AUTOSAR XML (schema 4-2-2)
package /ComponentTypes
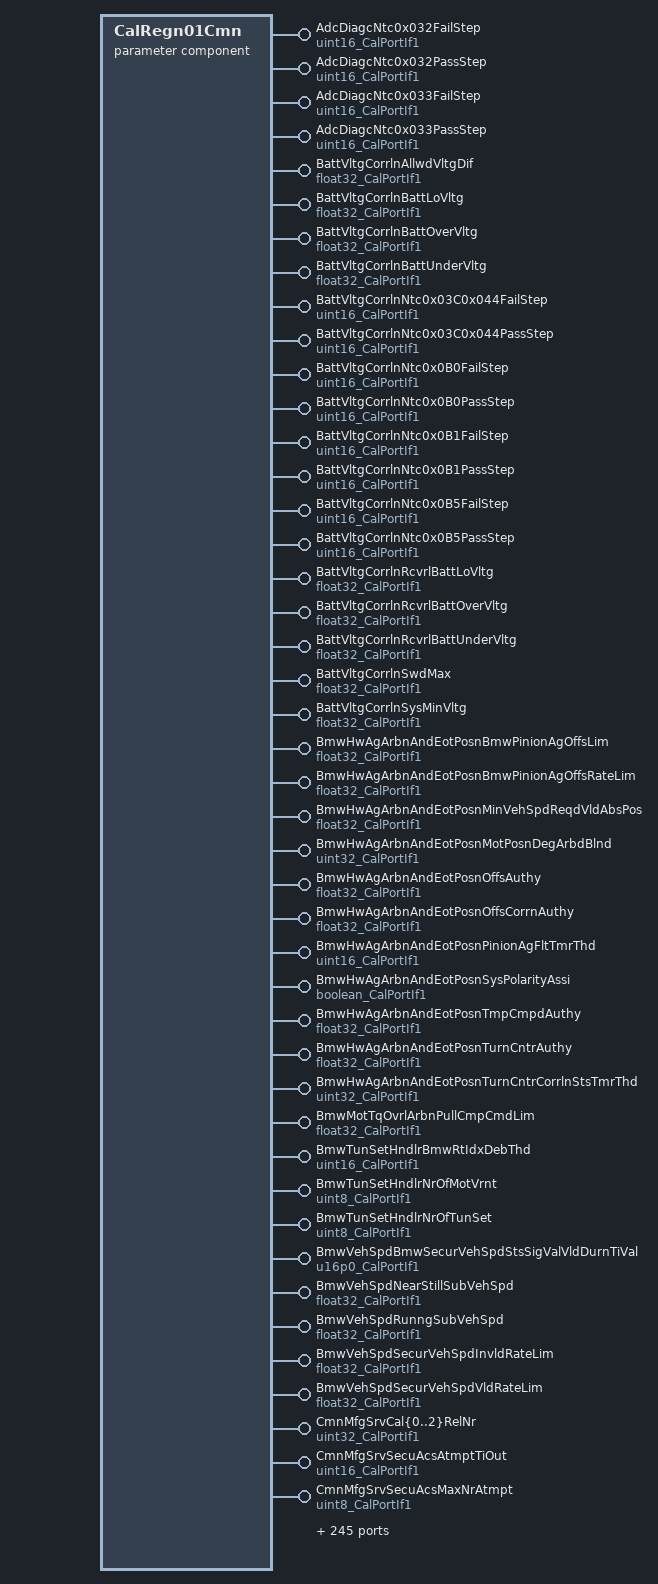
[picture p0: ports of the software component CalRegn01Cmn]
  parameter sw component type CalRegn01Cmn
    293 x provide port:
      AdcDiagcNtc0x032FailStep: parameter-provide-com-spec{init-value=6554, parameter=Val}, provided-interface=uint16_CalPortIf1
      AdcDiagcNtc0x032PassStep: parameter-provide-com-spec{init-value=65, parameter=Val}, provided-interface=uint16_CalPortIf1
      AdcDiagcNtc0x033FailStep: parameter-provide-com-spec{init-value=6554, parameter=Val}, provided-interface=uint16_CalPortIf1
      AdcDiagcNtc0x033PassStep: parameter-provide-com-spec{init-value=65, parameter=Val}, provided-interface=uint16_CalPortIf1
      BattVltgCorrlnAllwdVltgDif: parameter-provide-com-spec{init-value=0.73, parameter=Val}, provided-interface=float32_CalPortIf1
      BattVltgCorrlnBattLoVltg: parameter-provide-com-spec{init-value=10, parameter=Val}, provided-interface=float32_CalPortIf1
      BattVltgCorrlnBattOverVltg: parameter-provide-com-spec{init-value=16, parameter=Val}, provided-interface=float32_CalPortIf1
      BattVltgCorrlnBattUnderVltg: parameter-provide-com-spec{init-value=9, parameter=Val}, provided-interface=float32_CalPortIf1
      BattVltgCorrlnNtc0x03C0x044FailStep: parameter-provide-com-spec{init-value=410, parameter=Val}, provided-interface=uint16_CalPortIf1
      BattVltgCorrlnNtc0x03C0x044PassStep: parameter-provide-com-spec{init-value=272, parameter=Val}, provided-interface=uint16_CalPortIf1
      BattVltgCorrlnNtc0x0B0FailStep: parameter-provide-com-spec{init-value=327, parameter=Val}, provided-interface=uint16_CalPortIf1
      BattVltgCorrlnNtc0x0B0PassStep: parameter-provide-com-spec{init-value=327, parameter=Val}, provided-interface=uint16_CalPortIf1
      BattVltgCorrlnNtc0x0B1FailStep: parameter-provide-com-spec{init-value=327, parameter=Val}, provided-interface=uint16_CalPortIf1
      BattVltgCorrlnNtc0x0B1PassStep: parameter-provide-com-spec{init-value=327, parameter=Val}, provided-interface=uint16_CalPortIf1
      BattVltgCorrlnNtc0x0B5FailStep: parameter-provide-com-spec{init-value=327, parameter=Val}, provided-interface=uint16_CalPortIf1
      BattVltgCorrlnNtc0x0B5PassStep: parameter-provide-com-spec{init-value=327, parameter=Val}, provided-interface=uint16_CalPortIf1
      BattVltgCorrlnRcvrlBattLoVltg: parameter-provide-com-spec{init-value=10.5, parameter=Val}, provided-interface=float32_CalPortIf1
      BattVltgCorrlnRcvrlBattOverVltg: parameter-provide-com-spec{init-value=15.5, parameter=Val}, provided-interface=float32_CalPortIf1
      BattVltgCorrlnRcvrlBattUnderVltg: parameter-provide-com-spec{init-value=9.5, parameter=Val}, provided-interface=float32_CalPortIf1
      BattVltgCorrlnSwdMax: parameter-provide-com-spec{init-value=16, parameter=Val}, provided-interface=float32_CalPortIf1
      BattVltgCorrlnSysMinVltg: parameter-provide-com-spec{init-value=6, parameter=Val}, provided-interface=float32_CalPortIf1
      BmwHwAgArbnAndEotPosnBmwPinionAgOffsLim: parameter-provide-com-spec{init-value=0, parameter=Val}, provided-interface=float32_CalPortIf1
      BmwHwAgArbnAndEotPosnBmwPinionAgOffsRateLim: parameter-provide-com-spec{init-value=50, parameter=Val}, provided-interface=float32_CalPortIf1
      BmwHwAgArbnAndEotPosnMinVehSpdReqdVldAbsPos: parameter-provide-com-spec{init-value=18, parameter=Val}, provided-interface=float32_CalPortIf1
      BmwHwAgArbnAndEotPosnMotPosnDegArbdBlnd: parameter-provide-com-spec{init-value=200, parameter=Val}, provided-interface=uint32_CalPortIf1
      BmwHwAgArbnAndEotPosnOffsAuthy: parameter-provide-com-spec{init-value=1, parameter=Val}, provided-interface=float32_CalPortIf1
      BmwHwAgArbnAndEotPosnOffsCorrnAuthy: parameter-provide-com-spec{init-value=0.8, parameter=Val}, provided-interface=float32_CalPortIf1
      BmwHwAgArbnAndEotPosnPinionAgFltTmrThd: parameter-provide-com-spec{init-value=20, parameter=Val}, provided-interface=uint16_CalPortIf1
      BmwHwAgArbnAndEotPosnSysPolarityAssi: parameter-provide-com-spec{init-value=1, parameter=Logl}, provided-interface=boolean_CalPortIf1
      BmwHwAgArbnAndEotPosnTmpCmpdAuthy: parameter-provide-com-spec{init-value=0.6, parameter=Val}, provided-interface=float32_CalPortIf1
      BmwHwAgArbnAndEotPosnTurnCntrAuthy: parameter-provide-com-spec{init-value=1, parameter=Val}, provided-interface=float32_CalPortIf1
      BmwHwAgArbnAndEotPosnTurnCntrCorrlnStsTmrThd: parameter-provide-com-spec{init-value=50, parameter=Val}, provided-interface=uint32_CalPortIf1
      BmwMotTqOvrlArbnPullCmpCmdLim: parameter-provide-com-spec{init-value=8.8, parameter=Val}, provided-interface=float32_CalPortIf1
      BmwTunSetHndlrBmwRtIdxDebThd: parameter-provide-com-spec{init-value=120, parameter=Val}, provided-interface=uint16_CalPortIf1
      BmwTunSetHndlrNrOfMotVrnt: parameter-provide-com-spec{init-value=4, parameter=Val}, provided-interface=uint8_CalPortIf1
      BmwTunSetHndlrNrOfTunSet: parameter-provide-com-spec{init-value=7, parameter=Val}, provided-interface=uint8_CalPortIf1
      BmwVehSpdBmwSecurVehSpdStsSigValVldDurnTiVal: parameter-provide-com-spec{init-value=300, parameter=Val}, provided-interface=u16p0_CalPortIf1
      BmwVehSpdNearStillSubVehSpd: parameter-provide-com-spec{init-value=9, parameter=Val}, provided-interface=float32_CalPortIf1
      BmwVehSpdRunngSubVehSpd: parameter-provide-com-spec{init-value=130, parameter=Val}, provided-interface=float32_CalPortIf1
      BmwVehSpdSecurVehSpdInvldRateLim: parameter-provide-com-spec{init-value=50, parameter=Val}, provided-interface=float32_CalPortIf1
      BmwVehSpdSecurVehSpdVldRateLim: parameter-provide-com-spec{init-value=50, parameter=Val}, provided-interface=float32_CalPortIf1
      CmnMfgSrvCal{0..2}RelNr: parameter-provide-com-spec{init-value=0, parameter=Val}, provided-interface=uint32_CalPortIf1
      CmnMfgSrvSecuAcsAtmptTiOut: parameter-provide-com-spec{init-value=0, parameter=Val}, provided-interface=uint16_CalPortIf1
      CmnMfgSrvSecuAcsMaxNrAtmpt: parameter-provide-com-spec{init-value=0, parameter=Val}, provided-interface=uint8_CalPortIf1
      CmplncErrHwAgNonLinCmplncDepTblY: parameter-provide-com-spec{init-value=6 x 0, parameter=Ary1D}, provided-interface=Ary1D_u1p15_6_CalPortIf1
      CmplncErrHwAgNonLinCmplncIndTblX: parameter-provide-com-spec{init-value=[0, 1024, 3072, 6144, 10240, 16384], parameter=Ary1D}, provided-interface=Ary1D_u5p11_6_CalPortIf1
      CmplncErrMotAgNonLinCmplncDepTblY: parameter-provide-com-spec{init-value=6 x 0, parameter=Ary1D}, provided-interface=Ary1D_u8p8_6_CalPortIf1
      CmplncErrMotAgNonLinCmplncIndTblX: parameter-provide-com-spec{init-value=[0, 1024, 3072, 6144, 10240, 16384], parameter=Ary1D}, provided-interface=Ary1D_u5p11_6_CalPortIf1
      CurrMeasArbnMaxStallCntr: parameter-provide-com-spec{init-value=20, parameter=Val}, provided-interface=uint8_CalPortIf1
      CurrMeasCorrlnMaxErrCurr: parameter-provide-com-spec{init-value=12, parameter=Val}, provided-interface=float32_CalPortIf1
      CurrMeasCorrlnMaxStallCntr: parameter-provide-com-spec{init-value=200, parameter=Val}, provided-interface=uint8_CalPortIf1
      CurrMeasCorrlnNtc0x04DFailStep: parameter-provide-com-spec{init-value=512, parameter=Val}, provided-interface=uint16_CalPortIf1
      CurrMeasCorrlnNtc0x04DPassStep: parameter-provide-com-spec{init-value=512, parameter=Val}, provided-interface=uint16_CalPortIf1
      CurrMeasEolFixdPwmPerd: parameter-provide-com-spec{init-value=62500, parameter=Val}, provided-interface=uint32_CalPortIf1
      CurrMeasEolGainMax: parameter-provide-com-spec{init-value=76, parameter=Val}, provided-interface=float32_CalPortIf1
      CurrMeasEolGainMin: parameter-provide-com-spec{init-value=56, parameter=Val}, provided-interface=float32_CalPortIf1
      CurrMeasEolGainNom: parameter-provide-com-spec{init-value=66.66, parameter=Val}, provided-interface=float32_CalPortIf1
      CurrMeasEolGainNrOfSample: parameter-provide-com-spec{init-value=5, parameter=Val}, provided-interface=uint16_CalPortIf1
      CurrMeasEolGainNumer: parameter-provide-com-spec{init-value=45, parameter=Val}, provided-interface=float32_CalPortIf1
      CurrMeasEolMaxMotVel: parameter-provide-com-spec{init-value=16, parameter=Val}, provided-interface=float32_CalPortIf1
      CurrMeasEolOffsHiBrdgVltgMin: parameter-provide-com-spec{init-value=262500, parameter=Val}, provided-interface=float32_CalPortIf1
      CurrMeasEolOffsHiCmuOffs: parameter-provide-com-spec{init-value=50000, parameter=Val}, provided-interface=uint32_CalPortIf1
      CurrMeasEolOffsLoCmuOffs: parameter-provide-com-spec{init-value=6250, parameter=Val}, provided-interface=uint32_CalPortIf1
      CurrMeasEolOffsMax: parameter-provide-com-spec{init-value=2.8, parameter=Val}, provided-interface=float32_CalPortIf1
      CurrMeasEolOffsMin: parameter-provide-com-spec{init-value=2.3, parameter=Val}, provided-interface=float32_CalPortIf1
      CurrMeasEolOffsNom: parameter-provide-com-spec{init-value=2.5, parameter=Val}, provided-interface=float32_CalPortIf1
      CurrMeasEolOffsNrOfSample: parameter-provide-com-spec{init-value=20, parameter=Val}, provided-interface=uint16_CalPortIf1
      CurrMeasEolTranCntrThd: parameter-provide-com-spec{init-value=5, parameter=Val}, provided-interface=uint8_CalPortIf1
      CurrMeasMinRqrdPhaOnTi: parameter-provide-com-spec{init-value=11000, parameter=Val}, provided-interface=uint32_CalPortIf1
      CurrMeasMotAgCompuDly: parameter-provide-com-spec{init-value=30000, parameter=Val}, provided-interface=uint32_CalPortIf1
      CurrMeasMotCurrAdcVlyWrmIninMax: parameter-provide-com-spec{init-value=3, parameter=Val}, provided-interface=float32_CalPortIf1
      CurrMeasMotCurrAdcVlyWrmIninMin: parameter-provide-com-spec{init-value=2, parameter=Val}, provided-interface=float32_CalPortIf1
      CurrMeasNtc0x05DFailStep: parameter-provide-com-spec{init-value=16384, parameter=Val}, provided-interface=uint16_CalPortIf1
      CurrMeasNtc0x05DPassStep: parameter-provide-com-spec{init-value=16384, parameter=Val}, provided-interface=uint16_CalPortIf1
      DiagcMgrFltResp: parameter-provide-com-spec{init-value=[0, 34560, 34560, 34560, 34560, 34560, 34560, 34560, 34560, 34560, 34560, 34560, 34560, 34560, 34560, 34560, 34560, 34560, 34560, 34560, 34560, 34560, 34560, 34560, 34560, 34560, 34560, 34560, 34560, 34560, 34560, 34560, 34560, 34560, 34560, 34560, 34560, 34560, 34560, 34560, 34560, 34560, 34560, 34560, 34560, 34560, 34560, 34560, 34560, 34560, 34560, 34560, 34560, 34560, 34560, 34560, 34560, 34560, 34560, 34560, 34560, 34560, 34560, 34560, 34560, 34560, 34560, 34560, 34560, 34560, 34560, 34560, 34560, 34560, 34560, 34560, 34560, 34560, 34560, 34560, 34560, 34560, 34560, 34560, 34560, 34560, 34560, 34560, 34560, 34560, 34560, 34560, 34560, 34560, 34560, 34560, 34560, 34560, 34560, 34560, 34560, 34560, 34560, 34560, 34560, 34560, 34560, 34560, 34560, 34560, 34560, 34560, 34560, 34560, 34560, 34560, 34560, 34560, 34560, 34560, 34560, 34560, 34560, 34560, 34560, 34560, 34560, 34560, 34560, 34560, 34560, 34560, 34560, 34560, 34560, 34560, 34560, 34560, 34560, 34560, 34560, 34560, 34560, 34560, 34560, 34560, 34560, 34560, 34560, 34560, 34560, 34560, 34560, 34560, 34560, 34560, 34560, 34560, 34560, 34560, 34560, 34560, 34560, 34560, 34560, 34560, 34560, 34560, 34560, 34560, 34560, 34560, 34560, 34560, 34560, 34560, 34560, 34560, 34560, 34560, 34560, 34560, 34560, 34560, 34560, 34560, 34560, 34560, 34560, 34560, 34560, 34560, 34560, 34560, 34560, 34560, 34560, 34560, 34560, 34560, 34560, 34560, 34560, 34560, 34560, 34560, 34560, 34560, 34560, 34560, 34560, 34560, 34560, 34560, 34560, 34560, 34560, 34560, 34560, 34560, 34560, 34560, 34560, 34560, 34560, 34560, 34560, 34560, 34560, 34560, 34560, 34560, 34560, 34560, 34560, 34560, 34560, 34560, 34560, 34560, 34560, 34560, 34560, 34560, 34560, 34560, 34560, 34560, 34560, 34560, 34560, 34560, 34560, 34560, 34560, 34560, 34560, 34560, 34560, 34560, 34560, 34560, 34560, 34560, 34560, 34560, 34560, 34560, 34560, 34560, 34560, 34560, 34560, 34560, 34560, 34560, 34560, 34560, 34560, 34560, 34560, 34560, 34560, 34560, 34560, 34560, 34560, 34560, 34560, 34560, 34560, 34560, 34560, 34560, 34560, 34560, 34560, 34560, 34560, 34560, 34560, 34560, 34560, 34560, 34560, 34560, 34560, 34560, 34560, 34560, 34560, 34560, 34560, 34560, 34560, 34560, 34560, 34560, 34560, 34560, 34560, 34560, 34560, 34560, 34560, 34560, 34560, 34560, 34560, 34560, 34560, 34560, 34560, 34560, 34560, 34560, 34560, 34560, 34560, 34560, 34560, 34560, 34560, 34560, 34560, 34560, 34560, 34560, 34560, 34560, 34560, 34560, 34560, 34560, 34560, 34560, 34560, 34560, 34560, 34560, 34560, 34560, 34560, 34560, 34560, 34560, 34560, 34560, 34560, 34560, 34560, 34560, 34560, 34560, 34560, 34560, 34560, 34560, 34560, 34560, 34560, 34560, 34560, 34560, 34560, 34560, 34560, 34560, 34560, 34560, 34560, 34560, 34560, 34560, 34560, 34560, 34560, 34560, 34560, 34560, 34560, 34560, 34560, 34560, 34560, 34560, 34560, 34560, 34560, 34560, 34560, 34560, 34560, 34560, 34560, 34560, 34560, 34560, 34560, 34560, 34560, 34560, 34560, 34560, 34560, 34560, 34560, 34560, 34560, 34560, 34560, 34560, 34560, 34560, 34560, 34560, 34560, 34560, 34560, 34560, 34560, 34560, 34560, 34560, 34560, 34560, 34560, 34560, 34560, 34560, 34560, 34560, 34560, 34560, 34560, 34560, 34560, 34560, 34560, 34560, 34560, 34560, 34560, 34560, 34560, 34560, 34560, 34560, 34560, 34560, 34560, 34560, 34560, 34560, 34560, 34560, 34560, 34560, 34560, 34560, 34560, 34560, 34560, 34560, 34560, 34560, 34560, 34560, 34560, 34560, 34560, 34560, 34560, 34560, 34560, 34560, 34560, 34560, 34560, 34560, 34560, 34560, 34560, 34560, 34560, 34560, 34560, 34560, 34560, 34560, 34560, 34560], parameter=Ary1D}, provided-interface=Ary1D_u16_512_CalPortIf1
      ElecPwrCnsCtrlrInpR: parameter-provide-com-spec{init-value=0.0005, parameter=Val}, provided-interface=float32_CalPortIf1
      GateDrv0CtrlErrFilFrq: parameter-provide-com-spec{init-value=1.8, parameter=Val}, provided-interface=float32_CalPortIf1
      GateDrv0CtrlErrOffs: parameter-provide-com-spec{init-value=0, parameter=Val}, provided-interface=uint32_CalPortIf1
      GateDrv0CtrlErrThd: parameter-provide-com-spec{init-value=180000, parameter=Val}, provided-interface=uint32_CalPortIf1
      GateDrv0CtrlNtcNr0x050FailStep: parameter-provide-com-spec{init-value=4096, parameter=Val}, provided-interface=uint16_CalPortIf1
      GateDrv0CtrlNtcNr0x050PassStep: parameter-provide-com-spec{init-value=2048, parameter=Val}, provided-interface=uint16_CalPortIf1
      GateDrv0CtrlNtcNr0x051FailStep: parameter-provide-com-spec{init-value=4096, parameter=Val}, provided-interface=uint16_CalPortIf1
      GateDrv0CtrlNtcNr0x051PassStep: parameter-provide-com-spec{init-value=2048, parameter=Val}, provided-interface=uint16_CalPortIf1
      GateDrv0CtrlNtcNr0x055FailStep: parameter-provide-com-spec{init-value=4096, parameter=Val}, provided-interface=uint16_CalPortIf1
      GateDrv0CtrlNtcNr0x055PassStep: parameter-provide-com-spec{init-value=2048, parameter=Val}, provided-interface=uint16_CalPortIf1
      GateDrv0CtrlUnit0Cfg2WrVal: parameter-provide-com-spec{init-value=2832, parameter=Val}, provided-interface=uint16_CalPortIf1
      GateDrv0CtrlUnit0Cfg3WrVal: parameter-provide-com-spec{init-value=3598, parameter=Val}, provided-interface=uint16_CalPortIf1
      GateDrv0CtrlUnit0Cfg4WrVal: parameter-provide-com-spec{init-value=4622, parameter=Val}, provided-interface=uint16_CalPortIf1
      GateDrv0CtrlUnit0Cfg7WrVal: parameter-provide-com-spec{init-value=7924, parameter=Val}, provided-interface=uint16_CalPortIf1
      HiLoadStallLimrMotTqCmdFetMtgtnEnaFilFrq: parameter-provide-com-spec{init-value=2, parameter=Val}, provided-interface=float32_CalPortIf1
      HiLoadStallLimrMotTqCmdFilFrq: parameter-provide-com-spec{init-value=2, parameter=Val}, provided-interface=float32_CalPortIf1
      HwTq4MeasHwTq4PrtclFltFailStep: parameter-provide-com-spec{init-value=2521, parameter=Val}, provided-interface=uint16_CalPortIf1
      HwTq4MeasHwTq4PrtclFltPassStep: parameter-provide-com-spec{init-value=1000, parameter=Val}, provided-interface=uint16_CalPortIf1
      HwTq4MeasHwTqRngHiLim: parameter-provide-com-spec{init-value=4.75, parameter=Val}, provided-interface=float32_CalPortIf1
      HwTq4MeasHwTqRngLoLim: parameter-provide-com-spec{init-value=0.25, parameter=Val}, provided-interface=float32_CalPortIf1
      HwTq4MeasMovgAvrgFilEna: parameter-provide-com-spec{init-value=0, parameter=Logl}, provided-interface=boolean_CalPortIf1
      HwTq5MeasHwTq5PrtclFltFailStep: parameter-provide-com-spec{init-value=2521, parameter=Val}, provided-interface=uint16_CalPortIf1
      HwTq5MeasHwTq5PrtclFltPassStep: parameter-provide-com-spec{init-value=1000, parameter=Val}, provided-interface=uint16_CalPortIf1
      HwTq5MeasHwTqRngHiLim: parameter-provide-com-spec{init-value=4.75, parameter=Val}, provided-interface=float32_CalPortIf1
      HwTq5MeasHwTqRngLoLim: parameter-provide-com-spec{init-value=0.25, parameter=Val}, provided-interface=float32_CalPortIf1
      HwTq5MeasMovgAvrgFilEna: parameter-provide-com-spec{init-value=0, parameter=Logl}, provided-interface=boolean_CalPortIf1
      HwTqCorrlnChACmnModCmpLpFilActvnThd: parameter-provide-com-spec{init-value=0.2857143, parameter=Val}, provided-interface=float32_CalPortIf1
      HwTqCorrlnChACmnModCmpLpFilFrq: parameter-provide-com-spec{init-value=0.01989437, parameter=Val}, provided-interface=float32_CalPortIf1
      HwTqCorrlnChACmnModCmpLpFilOutpLim: parameter-provide-com-spec{init-value=0.5714, parameter=Val}, provided-interface=float32_CalPortIf1
      HwTqCorrlnChAImdtCorrlnChkFailThd: parameter-provide-com-spec{init-value=2.85, parameter=Val}, provided-interface=float32_CalPortIf1
      HwTqCorrlnChAImdtCorrlnChkPassThd: parameter-provide-com-spec{init-value=2, parameter=Val}, provided-interface=float32_CalPortIf1
      HwTqCorrlnChAStabStClrFltThd: parameter-provide-com-spec{init-value=2.515, parameter=Val}, provided-interface=float32_CalPortIf1
      HwTqCorrlnChAStabStLpFilFrq: parameter-provide-com-spec{init-value=0.01989437, parameter=Val}, provided-interface=float32_CalPortIf1
      HwTqCorrlnChAStabStSetFltThd: parameter-provide-com-spec{init-value=2.85, parameter=Val}, provided-interface=float32_CalPortIf1
      HwTqCorrlnChATqSumMaxLim: parameter-provide-com-spec{init-value=20, parameter=Val}, provided-interface=float32_CalPortIf1
      HwTqCorrlnChATraLpFilX: parameter-provide-com-spec{init-value=[0, 1783, 3560, 5342, 7125, 8902, 10685, 12467, 14245, 16027, 17810, 19587, 21370, 23152, 24935, 26712, 28495], parameter=Ary1D}, provided-interface=Ary1D_u5p11_17_CalPortIf1
      HwTqCorrlnChATraLpFilY: parameter-provide-com-spec{init-value=[34873, 34873, 34873, 34873, 19910, 12411, 9199, 7350, 6137, 5272, 4623, 4119, 3714, 3382, 3104, 2870, 2668], parameter=Ary1D}, provided-interface=Ary1D_u6p10_17_CalPortIf1
      HwTqCorrlnChATraSumClrFltThd: parameter-provide-com-spec{init-value=1.425, parameter=Val}, provided-interface=float32_CalPortIf1
      HwTqCorrlnChATraSumSetFltThd: parameter-provide-com-spec{init-value=2.85, parameter=Val}, provided-interface=float32_CalPortIf1
      LimrCdngGainDecSlew: parameter-provide-com-spec{init-value=500, parameter=Val}, provided-interface=float32_CalPortIf1
      LimrCdngGainIncSlewX: parameter-provide-com-spec{init-value=[1280, 2560], parameter=Ary1D}, provided-interface=Ary1D_u9p7_2_CalPortIf1
      LimrCdngGainIncSlewY: parameter-provide-com-spec{init-value=[64000, 64000], parameter=Ary1D}, provided-interface=Ary1D_u9p7_2_CalPortIf1
      LimrCdngTqDecSlew: parameter-provide-com-spec{init-value=4400, parameter=Val}, provided-interface=float32_CalPortIf1
      LimrCdngTqIncSlewX: parameter-provide-com-spec{init-value=[1280, 2560], parameter=Ary1D}, provided-interface=Ary1D_u9p7_2_CalPortIf1
      LimrCdngTqIncSlewY: parameter-provide-com-spec{init-value=[35200, 35200], parameter=Ary1D}, provided-interface=Ary1D_u13p3_2_CalPortIf1
      LoaMgrCurrIvtrMtgtnRate: parameter-provide-com-spec{init-value=1, parameter=Val}, provided-interface=float32_CalPortIf1
      LoaMgrCurrIvtrMtgtnSca: parameter-provide-com-spec{init-value=1, parameter=Val}, provided-interface=float32_CalPortIf1
      LoaMgrCurrIvtrMtgtnScaZeroEna: parameter-provide-com-spec{init-value=0, parameter=Logl}, provided-interface=boolean_CalPortIf1
      LoaMgrCurrMeasIdptSig0Resp: parameter-provide-com-spec{init-value=2, parameter=Val}, provided-interface=uint8_CalPortIf1
      LoaMgrCurrMeasIdptSig1Resp: parameter-provide-com-spec{init-value=0, parameter=Val}, provided-interface=uint8_CalPortIf1
      LoaMgrCurrMeasIdptSig2Resp: parameter-provide-com-spec{init-value=0, parameter=Val}, provided-interface=uint8_CalPortIf1
      LoaMgrCurrMeasIdptSigFltThd: parameter-provide-com-spec{init-value=0, parameter=Val}, provided-interface=uint8_CalPortIf1
      LoaMgrCurrMeasMtgtnRate: parameter-provide-com-spec{init-value=1, parameter=Val}, provided-interface=float32_CalPortIf1
      LoaMgrCurrMeasMtgtnSca: parameter-provide-com-spec{init-value=1, parameter=Val}, provided-interface=float32_CalPortIf1
      LoaMgrCurrMeasMtgtnScaZeroEna: parameter-provide-com-spec{init-value=1, parameter=Logl}, provided-interface=boolean_CalPortIf1
      LoaMgrFadeOutStRate: parameter-provide-com-spec{init-value=1, parameter=Val}, provided-interface=float32_CalPortIf1
      LoaMgrHwTqIdptSig0NoTqLoaResp: parameter-provide-com-spec{init-value=4, parameter=Val}, provided-interface=uint8_CalPortIf1
      LoaMgrHwTqIdptSig1NoTqLoaResp: parameter-provide-com-spec{init-value=4, parameter=Val}, provided-interface=uint8_CalPortIf1
      LoaMgrHwTqIdptSig{2..4}Resp: parameter-provide-com-spec{init-value=0, parameter=Val}, provided-interface=uint8_CalPortIf1
      LoaMgrHwTqIdptSigFltThd: parameter-provide-com-spec{init-value=1, parameter=Val}, provided-interface=uint8_CalPortIf1
      LoaMgrHwTqLoaAvlResp: parameter-provide-com-spec{init-value=2, parameter=Val}, provided-interface=uint8_CalPortIf1
      LoaMgrIvtrIdptSig0Resp: parameter-provide-com-spec{init-value=5, parameter=Val}, provided-interface=uint8_CalPortIf1
      LoaMgrIvtrIdptSig1Resp: parameter-provide-com-spec{init-value=2, parameter=Val}, provided-interface=uint8_CalPortIf1
      LoaMgrIvtrIdptSig2Resp: parameter-provide-com-spec{init-value=0, parameter=Val}, provided-interface=uint8_CalPortIf1
      LoaMgrIvtrIdptSigFltThd: parameter-provide-com-spec{init-value=0, parameter=Val}, provided-interface=uint8_CalPortIf1
      LoaMgrIvtrMtgtnRate: parameter-provide-com-spec{init-value=1, parameter=Val}, provided-interface=float32_CalPortIf1
      LoaMgrIvtrMtgtnSca: parameter-provide-com-spec{init-value=1, parameter=Val}, provided-interface=float32_CalPortIf1
      LoaMgrIvtrMtgtnScaZeroEna: parameter-provide-com-spec{init-value=0, parameter=Logl}, provided-interface=boolean_CalPortIf1
      LoaMgrLimdStRate: parameter-provide-com-spec{init-value=1, parameter=Val}, provided-interface=float32_CalPortIf1
      LoaMgrLimdStSca: parameter-provide-com-spec{init-value=1, parameter=Val}, provided-interface=float32_CalPortIf1
      LoaMgrMotAgAvlSnsrlsResp: parameter-provide-com-spec{init-value=2, parameter=Val}, provided-interface=uint8_CalPortIf1
      LoaMgrMotAgIdptSig0NoSnsrlsResp: parameter-provide-com-spec{init-value=5, parameter=Val}, provided-interface=uint8_CalPortIf1
      LoaMgrMotAgIdptSig1NoSnsrlsResp: parameter-provide-com-spec{init-value=5, parameter=Val}, provided-interface=uint8_CalPortIf1
      LoaMgrMotAgIdptSig2Resp: parameter-provide-com-spec{init-value=1, parameter=Val}, provided-interface=uint8_CalPortIf1
      LoaMgrMotAgIdptSig3Resp: parameter-provide-com-spec{init-value=0, parameter=Val}, provided-interface=uint8_CalPortIf1
      LoaMgrMotAgIdptSigFltThd: parameter-provide-com-spec{init-value=2, parameter=Val}, provided-interface=uint8_CalPortIf1
      LoaMgrMotAgMtgtnRate: parameter-provide-com-spec{init-value=1, parameter=Val}, provided-interface=float32_CalPortIf1
      LoaMgrMotAgMtgtnSca: parameter-provide-com-spec{init-value=1, parameter=Val}, provided-interface=float32_CalPortIf1
      LoaMgrMotAgMtgtnScaZeroEna: parameter-provide-com-spec{init-value=0, parameter=Logl}, provided-interface=boolean_CalPortIf1
      LrndRackCentrAllwManIniLrng: parameter-provide-com-spec{init-value=1, parameter=Logl}, provided-interface=boolean_CalPortIf1
      LrndRackCentrConfTrvlThd: parameter-provide-com-spec{init-value=800, parameter=Val}, provided-interface=float32_CalPortIf1
      LrndRackCentrHwAgFilFrq: parameter-provide-com-spec{init-value=1, parameter=Val}, provided-interface=float32_CalPortIf1
      LrndRackCentrMinMaxAdjmtFac: parameter-provide-com-spec{init-value=0.25, parameter=Val}, provided-interface=float32_CalPortIf1
      LrndRackCentrRackCentrPosnChgAllwd: parameter-provide-com-spec{init-value=3, parameter=Val}, provided-interface=float32_CalPortIf1
      LrndRackCentrTiThd: parameter-provide-com-spec{init-value=200, parameter=Val}, provided-interface=uint16_CalPortIf1
      LrnPinionCentrDampgCtrlGain: parameter-provide-com-spec{init-value=0, parameter=Val}, provided-interface=float32_CalPortIf1
      LrnPinionCentrHldTq: parameter-provide-com-spec{init-value=0, parameter=Val}, provided-interface=float32_CalPortIf1
      LrnPinionCentrHldTqErrThd: parameter-provide-com-spec{init-value=1, parameter=Val}, provided-interface=float32_CalPortIf1
      LrnPinionCentrHldTqRateLim: parameter-provide-com-spec{init-value=100, parameter=Val}, provided-interface=float32_CalPortIf1
      LrnPinionCentrHwPosnErrThd: parameter-provide-com-spec{init-value=100, parameter=Val}, provided-interface=float32_CalPortIf1
      LrnPinionCentrIntglCtrlGain: parameter-provide-com-spec{init-value=0, parameter=Val}, provided-interface=float32_CalPortIf1
      LrnPinionCentrMaxTqCmd: parameter-provide-com-spec{init-value=0, parameter=Val}, provided-interface=float32_CalPortIf1
      LrnPinionCentrMinMotTq: parameter-provide-com-spec{init-value=0.01, parameter=Val}, provided-interface=float32_CalPortIf1
      LrnPinionCentrMotVelThd: parameter-provide-com-spec{init-value=500, parameter=Val}, provided-interface=float32_CalPortIf1
      LrnPinionCentrPropCtrlGain: parameter-provide-com-spec{init-value=5, parameter=Val}, provided-interface=float32_CalPortIf1
      LrnPinionCentrTiOutThd: parameter-provide-com-spec{init-value=200, parameter=Val}, provided-interface=uint16_CalPortIf1
      LrnPinionCentrTiThd: parameter-provide-com-spec{init-value=100, parameter=Val}, provided-interface=uint16_CalPortIf1
      McuDiagc2MilliSecCntrCompThd: parameter-provide-com-spec{init-value=5, parameter=Val}, provided-interface=uint16_CalPortIf1
      McuDiagcFltFailStep: parameter-provide-com-spec{init-value=16385, parameter=Val}, provided-interface=uint16_CalPortIf1
      McuDiagcFltPassStep: parameter-provide-com-spec{init-value=160, parameter=Val}, provided-interface=uint16_CalPortIf1
      MotAg0MeasSnsrIfErrNtcMask: parameter-provide-com-spec{init-value=512, parameter=Val}, provided-interface=uint16_CalPortIf1
      MotAg1MeasOffs: parameter-provide-com-spec{init-value=32768, parameter=Val}, provided-interface=u0p16_CalPortIf1
      MotAg1MeasSnsrIfErrNtcMask: parameter-provide-com-spec{init-value=512, parameter=Val}, provided-interface=uint16_CalPortIf1
      MotCtrlPrmEstimnFetThermCoeff: parameter-provide-com-spec{init-value=0.005, parameter=Val}, provided-interface=float32_CalPortIf1
      MotCtrlPrmEstimnMagThermCoeff: parameter-provide-com-spec{init-value=-0.001, parameter=Val}, provided-interface=float32_CalPortIf1
      MotCurrRegCfgCtrlrDynGainVehSpdCutOff: parameter-provide-com-spec{init-value=255, parameter=Val}, provided-interface=float32_CalPortIf1
      MotCurrRegCfgCurrLoopSecOrderTrfFctEna: parameter-provide-com-spec{init-value=1, parameter=Logl}, provided-interface=boolean_CalPortIf1
      MotCurrRegCfgIntglGainSampleTi: parameter-provide-com-spec{init-value=0.000125, parameter=Val}, provided-interface=float32_CalPortIf1
      MotCurrRegCfgMotAgCompuDly: parameter-provide-com-spec{init-value=9.375e-05, parameter=Val}, provided-interface=float32_CalPortIf1
      MotCurrRegCfgMotCtrlPrmSelnX: parameter-provide-com-spec{init-value=[0, 32, 160, 320], parameter=Ary1D}, provided-interface=Ary1D_u11p5_4_CalPortIf1
      MotCurrRegVltgLimrMotCurrPredEna: parameter-provide-com-spec{init-value=0, parameter=Logl}, provided-interface=boolean_CalPortIf1
      MotCurrRegVltgLimrMotCurrPredTi: parameter-provide-com-spec{init-value=0, parameter=Val}, provided-interface=float32_CalPortIf1
      MotCurrRegVltgLimrMotCurrQaxRefMdfnRplEna: parameter-provide-com-spec{init-value=0, parameter=Logl}, provided-interface=boolean_CalPortIf1
      MotCurrRegVltgLimrMotVltgBrdgFilEna: parameter-provide-com-spec{init-value=1, parameter=Logl}, provided-interface=boolean_CalPortIf1
      MotCurrRegVltgLimrMotVltgQaxFfFilEna: parameter-provide-com-spec{init-value=1, parameter=Logl}, provided-interface=boolean_CalPortIf1
      MotQuadDetnMotDirHysInsts: parameter-provide-com-spec{init-value=20480, parameter=Val}, provided-interface=s18p13_CalPortIf1
      MotRefMdlFbCtrlDi: parameter-provide-com-spec{init-value=0, parameter=Logl}, provided-interface=boolean_CalPortIf1
      MotRefMdlIvtrDeadTiBrdgVltgSca: parameter-provide-com-spec{init-value=1, parameter=Val}, provided-interface=float32_CalPortIf1
      MotRefMdlMinCurrItrnLim: parameter-provide-com-spec{init-value=3, parameter=Val}, provided-interface=uint8_CalPortIf1
      MotRefMdlMotVelLpFilFrq: parameter-provide-com-spec{init-value=125, parameter=Val}, provided-interface=float32_CalPortIf1
      MotRefMdlMotVltgDerivtvTiCon: parameter-provide-com-spec{init-value=0.0026526, parameter=Val}, provided-interface=float32_CalPortIf1
      MotRefMdlRefLocnItrnLim: parameter-provide-com-spec{init-value=10, parameter=Val}, provided-interface=uint8_CalPortIf1
      MotRefMdlTqItrnLim: parameter-provide-com-spec{init-value=3, parameter=Val}, provided-interface=uint8_CalPortIf1
      MotRefMdlTqItrnTolr: parameter-provide-com-spec{init-value=0.015, parameter=Val}, provided-interface=float32_CalPortIf1
      MotRefMdlVltgModDynCmpEna: parameter-provide-com-spec{init-value=0, parameter=Logl}, provided-interface=boolean_CalPortIf1
      MotTqCmdScaMax: parameter-provide-com-spec{init-value=1.1, parameter=Val}, provided-interface=float32_CalPortIf1
      MotTqCmdScaMin: parameter-provide-com-spec{init-value=0.9, parameter=Val}, provided-interface=float32_CalPortIf1
      MotTqTranlDampgDampgCoeff: parameter-provide-com-spec{init-value=0.036, parameter=Val}, provided-interface=float32_CalPortIf1
      MotTqTranlDampgRampEnd: parameter-provide-com-spec{init-value=0, parameter=Val}, provided-interface=u2p14_CalPortIf1
      MotTqTranlDampgTmrPt1: parameter-provide-com-spec{init-value=100, parameter=Val}, provided-interface=float32_CalPortIf1
      MotTqTranlDampgTmrPt2: parameter-provide-com-spec{init-value=1000, parameter=Val}, provided-interface=float32_CalPortIf1
      MotTqTranlDampgVehSpdBlndX: parameter-provide-com-spec{init-value=[0, 1280, 2560, 12800], parameter=Ary1D}, provided-interface=Ary1D_u9p7_4_CalPortIf1
      MotTqTranlDampgVehSpdBlndY: parameter-provide-com-spec{init-value=[16384, 16384, 0, 0], parameter=Ary1D}, provided-interface=Ary1D_u2p14_4_CalPortIf1
      NxtrCalIdsCal0DevlpAuthor: parameter-provide-com-spec{init-value=6 x 0, parameter=Ary1D}, provided-interface=Ary1D_u08_6_CalPortIf1
      NxtrCalIdsCal0DevlpDesc: parameter-provide-com-spec{init-value=48 x 0, parameter=Ary1D}, provided-interface=Ary1D_u08_48_CalPortIf1
      NxtrCalIdsCal0DevlpRelNr: parameter-provide-com-spec{init-value=0, parameter=Val}, provided-interface=uint32_CalPortIf1
      NxtrCalIdsCal0DevlpRelSt: parameter-provide-com-spec{init-value=0, parameter=Val}, provided-interface=uint8_CalPortIf1
      NxtrCalIdsCal0DevlpTiStamp: parameter-provide-com-spec{init-value=0, parameter=Val}, provided-interface=uint32_CalPortIf1
      NxtrCalIdsCal0DevlpVers: parameter-provide-com-spec{init-value=0, parameter=Val}, provided-interface=uint8_CalPortIf1
      NxtrCalIdsCal1DevlpAuthor: parameter-provide-com-spec{init-value=6 x 0, parameter=Ary1D}, provided-interface=Ary1D_u08_6_CalPortIf1
      NxtrCalIdsCal1DevlpDesc: parameter-provide-com-spec{init-value=48 x 0, parameter=Ary1D}, provided-interface=Ary1D_u08_48_CalPortIf1
      NxtrCalIdsCal1DevlpRelNr: parameter-provide-com-spec{init-value=0, parameter=Val}, provided-interface=uint32_CalPortIf1
      NxtrCalIdsCal1DevlpRelSt: parameter-provide-com-spec{init-value=0, parameter=Val}, provided-interface=uint8_CalPortIf1
      NxtrCalIdsCal1DevlpTiStamp: parameter-provide-com-spec{init-value=0, parameter=Val}, provided-interface=uint32_CalPortIf1
      NxtrCalIdsCal1DevlpVers: parameter-provide-com-spec{init-value=0, parameter=Val}, provided-interface=uint8_CalPortIf1
      NxtrCalIdsCal2DevlpAuthor: parameter-provide-com-spec{init-value=6 x 0, parameter=Ary1D}, provided-interface=Ary1D_u08_6_CalPortIf1
      NxtrCalIdsCal2DevlpDesc: parameter-provide-com-spec{init-value=48 x 0, parameter=Ary1D}, provided-interface=Ary1D_u08_48_CalPortIf1
      NxtrCalIdsCal2DevlpRelNr: parameter-provide-com-spec{init-value=0, parameter=Val}, provided-interface=uint32_CalPortIf1
      NxtrCalIdsCal2DevlpRelSt: parameter-provide-com-spec{init-value=0, parameter=Val}, provided-interface=uint8_CalPortIf1
      NxtrCalIdsCal2DevlpTiStamp: parameter-provide-com-spec{init-value=0, parameter=Val}, provided-interface=uint32_CalPortIf1
      NxtrCalIdsCal2DevlpVers: parameter-provide-com-spec{init-value=0, parameter=Val}, provided-interface=uint8_CalPortIf1
      PhaDiscnctClsDlyTi: parameter-provide-com-spec{init-value=40, parameter=Val}, provided-interface=uint16_CalPortIf1
      PhaDiscnctFixdPhaOnTi: parameter-provide-com-spec{init-value=6250, parameter=Val}, provided-interface=uint32_CalPortIf1
      PhaDiscnctFixdPwmPerd: parameter-provide-com-spec{init-value=62500, parameter=Val}, provided-interface=uint32_CalPortIf1
      PhaDiscnctOpenDlyTi: parameter-provide-com-spec{init-value=40, parameter=Val}, provided-interface=uint16_CalPortIf1
      PhaDiscnctTestCurrTestVal: parameter-provide-com-spec{init-value=20, parameter=Val}, provided-interface=float32_CalPortIf1
      PhaDiscnctTestFailScanMax: parameter-provide-com-spec{init-value=2, parameter=Val}, provided-interface=uint8_CalPortIf1
      PhaDiscnctTestIninScan: parameter-provide-com-spec{init-value=3, parameter=Val}, provided-interface=uint8_CalPortIf1
      PhaDiscnctTestScanCnt: parameter-provide-com-spec{init-value=4, parameter=Val}, provided-interface=uint8_CalPortIf1
      PosnTrakgServoHwAgTarRateLimTblY: parameter-provide-com-spec{init-value=12 x 45000, parameter=Ary1D}, provided-interface=Ary1D_u15p1_12_CalPortIf1
      PosnTrakgServoHwVelTarRateLimTblY: parameter-provide-com-spec{init-value=12 x 45000, parameter=Ary1D}, provided-interface=Ary1D_u15p1_12_CalPortIf1
      PosnTrakgServoIntglLim: parameter-provide-com-spec{init-value=[24000, 20000, 16000, 12000, 8000, 8000, 8000, 8000, 8000, 8000, 8000, 8000], parameter=Ary1D}, provided-interface=Ary1D_u15p1_12_CalPortIf1
      PosnTrakgServoIntgtrAntiWdupGain: parameter-provide-com-spec{init-value=0, parameter=Val}, provided-interface=float32_CalPortIf1
      PosnTrakgServoIntgtrStCorrnGain: parameter-provide-com-spec{init-value=0.1, parameter=Val}, provided-interface=float32_CalPortIf1
      PosnTrakgServoLpFilCutOffFrq: parameter-provide-com-spec{init-value=250, parameter=Val}, provided-interface=float32_CalPortIf1
      PosnTrakgServoOutpAntiWdupGain: parameter-provide-com-spec{init-value=0, parameter=Val}, provided-interface=float32_CalPortIf1
      PosnTrakgServoOutpLim: parameter-provide-com-spec{init-value=12 x 32000, parameter=Ary1D}, provided-interface=Ary1D_u8p8_12_CalPortIf1
      PwrLimrSplyCurrLimTblX: parameter-provide-com-spec{init-value=[320, 480, 640, 800, 960, 1120, 1280, 1440, 1600, 1920], parameter=Ary1D}, provided-interface=Ary1D_u12p4_10_CalPortIf1
      PwrLimrSplyCurrLimTblY: parameter-provide-com-spec{init-value=[10304, 7874, 5864, 4106, 2848, 1742, 0, 0, 0, 0], parameter=Ary1D}, provided-interface=Ary1D_u11p5_10_CalPortIf1
      PwrSplyNtc0x07BFailStep: parameter-provide-com-spec{init-value=52424, parameter=Val}, provided-interface=uint16_CalPortIf1
      PwrSplyNtc0x07BPassStep: parameter-provide-com-spec{init-value=13106, parameter=Val}, provided-interface=uint16_CalPortIf1
      PwrSplyNtc0x07CFailStep: parameter-provide-com-spec{init-value=52424, parameter=Val}, provided-interface=uint16_CalPortIf1
      PwrSplyNtc0x07CPassStep: parameter-provide-com-spec{init-value=13106, parameter=Val}, provided-interface=uint16_CalPortIf1
      PwrSplyNtc0x07DFailStep: parameter-provide-com-spec{init-value=52424, parameter=Val}, provided-interface=uint16_CalPortIf1
      PwrSplyNtc0x07DPassStep: parameter-provide-com-spec{init-value=13106, parameter=Val}, provided-interface=uint16_CalPortIf1
      SinVltgGennDthrEna: parameter-provide-com-spec{init-value=1, parameter=Logl}, provided-interface=boolean_CalPortIf1
      SinVltgGennDthrLpFilCoeff: parameter-provide-com-spec{init-value=0.625, parameter=Val}, provided-interface=float32_CalPortIf1
      SysGlbPrmMotPoleCnt: parameter-provide-com-spec{init-value=6, parameter=Val}, provided-interface=uint8_CalPortIf1
      SysGlbPrmTorsBarStfn: parameter-provide-com-spec{init-value=2.5, parameter=Val}, provided-interface=float32_CalPortIf1
      SysKineAndEffCmplncErrDerivtvCutOffFrq: parameter-provide-com-spec{init-value=25, parameter=Val}, provided-interface=float32_CalPortIf1
      SysKineAndEffMotAgScaX: parameter-provide-com-spec{init-value=[-19165, -17140, -15133, -13160, -11221, -9315, -7436, -5574, -3715, -1857, 0, 1857, 3715, 5572, 7430, 9293, 11171, 13078, 15016, 16988, 18994], parameter=Ary1D}, provided-interface=Ary1D_s15p0_21_CalPortIf1
      SysKineAndEffMotToRackEffScaY: parameter-provide-com-spec{init-value=[27853, 27918, 27984, 28049, 28115, 28180, 28180, 28180, 28180, 28180, 28180, 28180, 28180, 28180, 28180, 28180, 28115, 28049, 27984, 27918, 27853], parameter=Ary1D}, provided-interface=Ary1D_u1p15_21_CalPortIf1
      SysKineAndEffRackPosScaY: parameter-provide-com-spec{init-value=[-12800, -11520, -10240, -8960, -7680, -6400, -5120, -3840, -2560, -1280, 0, 1280, 2560, 3840, 5120, 6400, 7680, 8960, 10240, 11520, 12800], parameter=Ary1D}, provided-interface=Ary1D_s8p7_21_CalPortIf1
      TEstimnIgnOffCtrlEna: parameter-provide-com-spec{init-value=0, parameter=Logl}, provided-interface=boolean_CalPortIf1
      TEstimnIgnOffMsgWaitTi: parameter-provide-com-spec{init-value=0.5, parameter=Val}, provided-interface=float32_CalPortIf1
      TqOscnAmpLimY: parameter-provide-com-spec{init-value=[819, 922, 1024, 1126, 1229, 1331, 1434, 1434, 1434, 1434, 1434], parameter=Ary1D}, provided-interface=Ary1D_u5p11_11_CalPortIf1
      TqOscnFallRampRateCal: parameter-provide-com-spec{init-value=-4400, parameter=Val}, provided-interface=float32_CalPortIf1
      TqOscnFrqIn: parameter-provide-com-spec{init-value=[2560, 3200, 3840, 4480, 5120, 6400, 7680, 8960, 10240, 11520, 12800], parameter=Ary1D}, provided-interface=Ary1D_u8p8_11_CalPortIf1
      TqOscnRisngRampRateCal: parameter-provide-com-spec{init-value=4400, parameter=Val}, provided-interface=float32_CalPortIf1
      TqOscnUseRampRateCal: parameter-provide-com-spec{init-value=1, parameter=Logl}, provided-interface=boolean_CalPortIf1
      TSG31CfgAndUseAdcStrtOfCnvn2Offs: parameter-provide-com-spec{init-value=5000, parameter=Val}, provided-interface=uint32_CalPortIf1
      TSG31CfgAndUseAdcStrtOfCnvnMotCtrlPeakOffs: parameter-provide-com-spec{init-value=6000, parameter=Val}, provided-interface=uint32_CalPortIf1
      TSG31CfgAndUseAdcStrtOfCnvnMotCtrlVlyOffs: parameter-provide-com-spec{init-value=7000, parameter=Val}, provided-interface=uint32_CalPortIf1
      TSG31CfgAndUseMtrAg0SPIStart: parameter-provide-com-spec{init-value=1000, parameter=Val}, provided-interface=uint32_CalPortIf1
      TSG31CfgAndUsePwmDbnd: parameter-provide-com-spec{init-value=200, parameter=Val}, provided-interface=uint32_CalPortIf1
      TunSelnAuthyHwTqY: parameter-provide-com-spec{init-value=6 x 20480, parameter=Ary1D}, provided-interface=Ary1D_u4p12_6_CalPortIf1
      TunSelnAuthyHwVelY: parameter-provide-com-spec{init-value=6 x 20480, parameter=Ary1D}, provided-interface=Ary1D_u6p10_6_CalPortIf1
      TunSelnAuthyTunSelnRtDiCmd: parameter-provide-com-spec{init-value=0, parameter=Logl}, provided-interface=boolean_CalPortIf1
      VehSigCdngDftLatA: parameter-provide-com-spec{init-value=0, parameter=Val}, provided-interface=float32_CalPortIf1
      VehSigCdngDftLgtA: parameter-provide-com-spec{init-value=0, parameter=Val}, provided-interface=float32_CalPortIf1
      VehSigCdngDftVehSpd: parameter-provide-com-spec{init-value=100, parameter=Val}, provided-interface=float32_CalPortIf1
      VehSigCdngDftYawRate: parameter-provide-com-spec{init-value=0, parameter=Val}, provided-interface=float32_CalPortIf1
      VehSigCdngLatADifThd: parameter-provide-com-spec{init-value=0.2, parameter=Val}, provided-interface=float32_CalPortIf1
      VehSigCdngLatAFilFrq: parameter-provide-com-spec{init-value=100, parameter=Val}, provided-interface=float32_CalPortIf1
      VehSigCdngLatASlewRate: parameter-provide-com-spec{init-value=10, parameter=Val}, provided-interface=float32_CalPortIf1
      VehSigCdngLtgADifThd: parameter-provide-com-spec{init-value=1, parameter=Val}, provided-interface=float32_CalPortIf1
      VehSigCdngLtgASlewRate: parameter-provide-com-spec{init-value=50, parameter=Val}, provided-interface=float32_CalPortIf1
      VehSigCdngVehSpdDifThd: parameter-provide-com-spec{init-value=5, parameter=Val}, provided-interface=float32_CalPortIf1
      VehSigCdngVehSpdSlewRate: parameter-provide-com-spec{init-value=50, parameter=Val}, provided-interface=float32_CalPortIf1
      VehSigCdngVehYawSlewRate: parameter-provide-com-spec{init-value=120, parameter=Val}, provided-interface=float32_CalPortIf1
      VehSigCdngYawRateDifThd: parameter-provide-com-spec{init-value=20, parameter=Val}, provided-interface=float32_CalPortIf1
      VehSpdLimrMaxAssiX: parameter-provide-com-spec{init-value=[0, 3200, 6400, 8320, 9600], parameter=Ary1D}, provided-interface=Ary1D_u9p7_5_CalPortIf1
      VehSpdLimrMaxAssiY: parameter-provide-com-spec{init-value=5 x 18022, parameter=Ary1D}, provided-interface=Ary1D_u5p11_5_CalPortIf1
      VehSpdLimrPosMaxOffs1: parameter-provide-com-spec{init-value=140, parameter=Val}, provided-interface=float32_CalPortIf1
